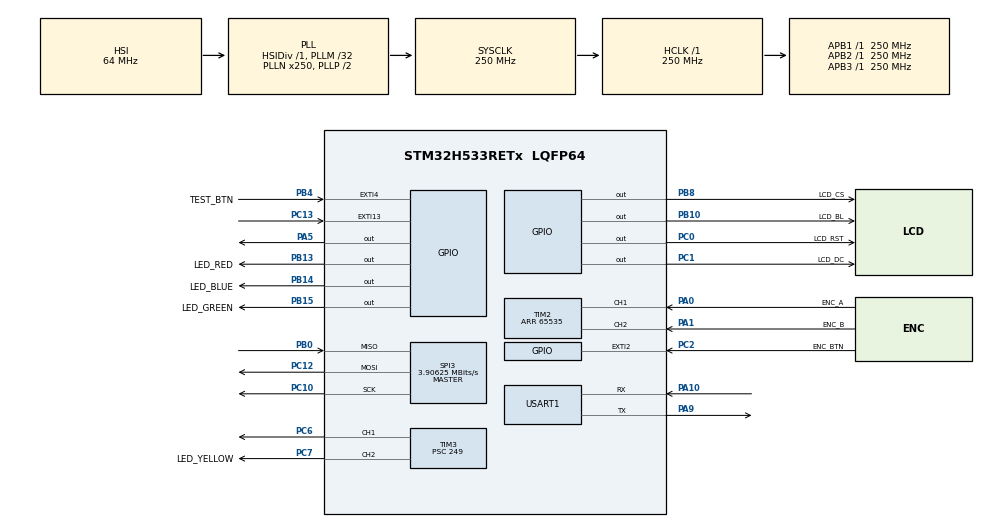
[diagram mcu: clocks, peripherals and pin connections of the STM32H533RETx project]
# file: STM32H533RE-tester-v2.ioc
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BOOTPATH.BootPathName=LEGACY
BOOTPATH.UserSelectedBootPath=LEGACY
CORTEX_M33_NS.userName=CORTEX_M33
GPDMA1.DESTBURSTLENGTH_GPDMACH0=1
GPDMA1.DESTINC_GPDMACH0=DMA_DINC_FIXED
GPDMA1.DIRECTION_GPDMACH0=DMA_MEMORY_TO_PERIPH
GPDMA1.IPHANDLE_GPDMACH0-SIMPLEREQUEST_GPDMACH0=__NULL
GPDMA1.REQUEST_GPDMACH0=GPDMA1_REQUEST_SPI3_TX
GPDMA1.SRCBURSTLENGTH_GPDMACH0=1
GPDMA1.SRCINC_GPDMACH0=DMA_SINC_INCREMENTED
Mcu.Family=STM32H5
Mcu.Name=STM32H533RETx
Mcu.Package=LQFP64
NUCLEO-H533RE.BUTTON=1
NUCLEO-H533RE.LD4=true
NUCLEO-H533RE.VCP=true
NVIC.EXTI13_IRQn=true\:0\:0\:false\:false\:true\:false\:true\:true
NVIC.EXTI2_IRQn=true\:0\:0\:false\:false\:true\:true\:true\:true
NVIC.EXTI4_IRQn=true\:0\:0\:false\:false\:true\:true\:true\:true
NVIC.GPDMA1_Channel0_IRQn=true\:0\:0\:false\:false\:true\:true\:true\:true
NVIC.PriorityGroup=NVIC_PRIORITYGROUP_4
NVIC.SPI3_IRQn=true\:0\:0\:false\:false\:true\:true\:true\:true
PA0.GPIO_Label=ENC_A
PA0.Signal=S_TIM2_CH1
PA1.GPIO_Label=ENC_B
PA1.Signal=S_TIM2_CH2
PA10.Mode=Asynchronous
PA10.Signal=USART1_RX
PA13(JTMS/SWDIO).GPIO_Label=SWDIO
PA13(JTMS/SWDIO).Signal=DEBUG_JTMS-SWDIO
PA14(JTCK/SWCLK).GPIO_Label=SWCLK
PA14(JTCK/SWCLK).Signal=DEBUG_JTCK-SWCLK
PA15(JTDI).GPIO_Label=JTDI
PA15(JTDI).Signal=DEBUG_JTDI
PA2.Signal=USART2_TX
PA3.Signal=USART2_RX
PA5.Signal=GPIO_Output
PA9.Mode=Asynchronous
PA9.Signal=USART1_TX
PB0.Mode=Full_Duplex_Master
PB0.Signal=SPI3_MISO
PB10.GPIO_Label=LCD_BL
PB10.Signal=GPIO_Output
PB13.GPIO_Label=LED_RED
PB13.PinState=GPIO_PIN_SET
PB13.Signal=GPIO_Output
PB14.GPIO_Label=LED_BLUE
PB14.PinState=GPIO_PIN_SET
PB14.Signal=GPIO_Output
PB15.GPIO_Label=LED_GREEN
PB15.PinState=GPIO_PIN_SET
PB15.Signal=GPIO_Output
PB3(JTDO/TRACESWO).GPIO_Label=SWO
PB3(JTDO/TRACESWO).Signal=DEBUG_JTDO-SWO
PB4(NJTRST).GPIO_Label=TEST_BTN
PB4(NJTRST).GPIO_ModeDefaultEXTI=GPIO_MODE_IT_FALLING
PB4(NJTRST).GPIO_PuPd=GPIO_PULLUP
PB4(NJTRST).Signal=GPXTI4
PB8.GPIO_Label=LCD_CS
PB8.Signal=GPIO_Output
PC0.GPIO_Label=LCD_RST
PC0.Signal=GPIO_Output
PC1.GPIO_Label=LCD_DC
PC1.Signal=GPIO_Output
PC10.Mode=Full_Duplex_Master
PC10.Signal=SPI3_SCK
PC12.Mode=Full_Duplex_Master
PC12.Signal=SPI3_MOSI
PC13.Signal=GPXTI13
PC2.GPIO_Label=ENC_BTN
PC2.GPIO_ModeDefaultEXTI=GPIO_MODE_IT_FALLING
PC2.GPIO_PuPd=GPIO_PULLUP
PC2.Signal=GPXTI2
PC6.Signal=S_TIM3_CH1
PC7.GPIO_Label=LED_YELLOW
PC7.Signal=S_TIM3_CH2
ProjectManager.HeapSize=0x200
ProjectManager.StackSize=0x400
ProjectManager.TargetToolchain=STM32CubeIDE
RCC.ADCFreq_Value=250000000
RCC.AHBFreq_Value=250000000
RCC.APB1Freq_Value=250000000
RCC.APB1TimFreq_Value=250000000
RCC.APB2Freq_Value=250000000
RCC.APB2TimFreq_Value=250000000
RCC.APB3Freq_Value=250000000
RCC.CSI_VALUE=4000000
RCC.CortexFreq_Value=250000000
RCC.EPOD_VALUE=64000000
RCC.HCLKFreq_Value=250000000
RCC.HSE_VALUE=8000000
RCC.HSI48_VALUE=48000000
RCC.HSIDiv=RCC_HSI_DIV1
RCC.HSI_VALUE=64000000
RCC.LSE_VALUE=32768
RCC.LSIRC_VALUE=32000
RCC.PLLM=32
RCC.PLLN=250
RCC.PLLSourceVirtual=RCC_PLL1_SOURCE_HSI
RCC.SYSCLKFreq_VALUE=250000000
RCC.SYSCLKSource=RCC_SYSCLKSOURCE_PLLCLK
RCC.USBFreq_Value=48000000
RCC.VCOOutputFreq_Value=500000000
SH.S_TIM2_CH1.0=TIM2_CH1,Encoder_Interface
SH.S_TIM2_CH2.0=TIM2_CH2,Encoder_Interface
SH.S_TIM3_CH1.0=TIM3_CH1,PWM Generation1 CH1
SH.S_TIM3_CH2.0=TIM3_CH2,PWM Generation2 CH2
SPI3.BaudRatePrescaler=SPI_BAUDRATEPRESCALER_64
SPI3.CLKPhase=SPI_PHASE_2EDGE
SPI3.CLKPolarity=SPI_POLARITY_HIGH
SPI3.CalculateBaudRate=3.90625 MBits/s
SPI3.DataSize=SPI_DATASIZE_8BIT
SPI3.Direction=SPI_DIRECTION_2LINES
SPI3.Mode=SPI_MODE_MASTER
SPI3.VirtualType=VM_MASTER
TIM2.PeriodNoDither=65535
TIM3.Channel-PWM\ Generation1\ CH1=TIM_CHANNEL_1
TIM3.Channel-PWM\ Generation2\ CH2=TIM_CHANNEL_2
TIM3.OCMode_PWM-PWM\ Generation1\ CH1=TIM_OCMODE_PWM1
TIM3.OCPolarity_2=TIM_OCPOLARITY_LOW
TIM3.PeriodNoDither=999
TIM3.Prescaler=249
TIM3.PulseNoDither_1=500
USART1.RxPinLevelInvertParam=ADVFEATURE_RXINV_DISABLE
USART1.TxPinLevelInvertParam=ADVFEATURE_TXINV_DISABLE
USART1.VirtualMode-Asynchronous=VM_ASYNC
VP_BOOTPATH_VS_BOOTPATH.Mode=BP_Activate
VP_CORTEX_M33_NS_VS_Hclk.Mode=Hclk_Mode
VP_GPDMA1_VS_GPDMACH0.Mode=SIMPLEREQUEST_GPDMACH0
VP_ICACHE_VS_ICACHE.Mode=DefaultMode
VP_MEMORYMAP_VS_MEMORYMAP.Mode=CurAppReg
VP_NUCLEO-H533RE_VS_BSP_COMMON.Mode=COMMON
VP_PWR_VS_LPOM.Mode=PowerOptimisation
VP_PWR_VS_SECSignals.Mode=Security/Privilege
VP_TIM3_VS_ClockSourceINT.Mode=Internal
board=NUCLEO-H533RE

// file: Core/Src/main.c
/* USER CODE BEGIN Header */
/**
  ******************************************************************************
  * @file           : main.c
  * @brief          : Main program body
  ******************************************************************************
  * @attention
  *
  * Copyright (c) 2025 STMicroelectronics.
  * All rights reserved.
  *
  * This software is licensed under terms that can be found in the LICENSE file
  * in the root directory of this software component.
  * If no LICENSE file comes with this software, it is provided AS-IS.
  *
  ******************************************************************************
  */
/* USER CODE END Header */
#include "main.h"

/* USER CODE BEGIN Includes */
#include "buttons.h"

/* USER CODE END Includes */

COM_InitTypeDef BspCOMInit;

SPI_HandleTypeDef hspi3;
DMA_HandleTypeDef handle_GPDMA1_Channel0;

TIM_HandleTypeDef htim2;
TIM_HandleTypeDef htim3;

UART_HandleTypeDef huart1;

void SystemClock_Config(void);
static void MX_GPIO_Init(void);
static void MX_GPDMA1_Init(void);
static void MX_ICACHE_Init(void);
static void MX_TIM3_Init(void);
static void MX_TIM2_Init(void);
static void MX_SPI3_Init(void);
static void MX_USART1_UART_Init(void);

int main(void)
{

  /* MCU Configuration--------------------------------------------------------*/

  /* Reset of all peripherals, Initializes the Flash interface and the Systick. */
  HAL_Init();

  /* Configure the system clock */
  SystemClock_Config();

  /* Initialize all configured peripherals */
  MX_GPIO_Init();
  MX_GPDMA1_Init();
  MX_ICACHE_Init();
  MX_TIM3_Init();
  MX_TIM2_Init();
  MX_SPI3_Init();
  MX_USART1_UART_Init();
  /* USER CODE BEGIN 2 */

  // Inicjalizacja warstwy aplikacji
  app_init();

  /* USER CODE END 2 */

  /* Initialize leds */
  BSP_LED_Init(LED_GREEN);

  /* Initialize USER push-button, will be used to trigger an interrupt each time it's pressed.*/
  BSP_PB_Init(BUTTON_USER, BUTTON_MODE_EXTI);

  /* Initialize COM1 port (115200, 8 bits (7-bit data + 1 stop bit), no parity */
  BspCOMInit.BaudRate   = 115200;
  BspCOMInit.WordLength = COM_WORDLENGTH_8B;
  BspCOMInit.StopBits   = COM_STOPBITS_1;
  BspCOMInit.Parity     = COM_PARITY_NONE;
  BspCOMInit.HwFlowCtl  = COM_HWCONTROL_NONE;
  if (BSP_COM_Init(COM1, &BspCOMInit) != BSP_ERROR_NONE)
  {
    Error_Handler();
  }

  /* Infinite loop */
  /* USER CODE BEGIN WHILE */
  while (1)
  {
    // Główna pętla aplikacji
    app_process();
    /* USER CODE END WHILE */

  }
}

void SystemClock_Config(void)
{
  RCC_OscInitTypeDef RCC_OscInitStruct = {0};
  RCC_ClkInitTypeDef RCC_ClkInitStruct = {0};

  /** Configure the main internal regulator output voltage
  */
  __HAL_PWR_VOLTAGESCALING_CONFIG(PWR_REGULATOR_VOLTAGE_SCALE0);

  while(!__HAL_PWR_GET_FLAG(PWR_FLAG_VOSRDY)) {}

  /** Initializes the RCC Oscillators according to the specified parameters
  * in the RCC_OscInitTypeDef structure.
  */
  RCC_OscInitStruct.OscillatorType = RCC_OSCILLATORTYPE_HSI;
  RCC_OscInitStruct.HSIState = RCC_HSI_ON;
  RCC_OscInitStruct.HSIDiv = RCC_HSI_DIV1;
  RCC_OscInitStruct.HSICalibrationValue = RCC_HSICALIBRATION_DEFAULT;
  RCC_OscInitStruct.PLL.PLLState = RCC_PLL_ON;
  RCC_OscInitStruct.PLL.PLLSource = RCC_PLL1_SOURCE_HSI;
  RCC_OscInitStruct.PLL.PLLM = 32;
  RCC_OscInitStruct.PLL.PLLN = 250;
  RCC_OscInitStruct.PLL.PLLP = 2;
  RCC_OscInitStruct.PLL.PLLQ = 2;
  RCC_OscInitStruct.PLL.PLLR = 2;
  RCC_OscInitStruct.PLL.PLLRGE = RCC_PLL1_VCIRANGE_1;
  RCC_OscInitStruct.PLL.PLLVCOSEL = RCC_PLL1_VCORANGE_WIDE;
  RCC_OscInitStruct.PLL.PLLFRACN = 0;
  if (HAL_RCC_OscConfig(&RCC_OscInitStruct) != HAL_OK)
  {
    Error_Handler();
  }

  /** Initializes the CPU, AHB and APB buses clocks
  */
  RCC_ClkInitStruct.ClockType = RCC_CLOCKTYPE_HCLK|RCC_CLOCKTYPE_SYSCLK
                              |RCC_CLOCKTYPE_PCLK1|RCC_CLOCKTYPE_PCLK2
                              |RCC_CLOCKTYPE_PCLK3;
  RCC_ClkInitStruct.SYSCLKSource = RCC_SYSCLKSOURCE_PLLCLK;
  RCC_ClkInitStruct.AHBCLKDivider = RCC_SYSCLK_DIV1;
  RCC_ClkInitStruct.APB1CLKDivider = RCC_HCLK_DIV1;
  RCC_ClkInitStruct.APB2CLKDivider = RCC_HCLK_DIV1;
  RCC_ClkInitStruct.APB3CLKDivider = RCC_HCLK_DIV1;

  if (HAL_RCC_ClockConfig(&RCC_ClkInitStruct, FLASH_LATENCY_5) != HAL_OK)
  {
    Error_Handler();
  }

  /** Configure the programming delay
  */
  __HAL_FLASH_SET_PROGRAM_DELAY(FLASH_PROGRAMMING_DELAY_2);
}

static void MX_GPDMA1_Init(void)
{

  /* Peripheral clock enable */
  __HAL_RCC_GPDMA1_CLK_ENABLE();

  /* GPDMA1 interrupt Init */
    HAL_NVIC_SetPriority(GPDMA1_Channel0_IRQn, 0, 0);
    HAL_NVIC_EnableIRQ(GPDMA1_Channel0_IRQn);

}

static void MX_ICACHE_Init(void)
{

  /** Enable instruction cache (default 2-ways set associative cache)
  */
  if (HAL_ICACHE_Enable() != HAL_OK)
  {
    Error_Handler();
  }

}

static void MX_SPI3_Init(void)
{

  /* SPI3 parameter configuration*/
  hspi3.Instance = SPI3;
  hspi3.Init.Mode = SPI_MODE_MASTER;
  hspi3.Init.Direction = SPI_DIRECTION_2LINES;
  hspi3.Init.DataSize = SPI_DATASIZE_8BIT;
  hspi3.Init.CLKPolarity = SPI_POLARITY_HIGH;
  hspi3.Init.CLKPhase = SPI_PHASE_2EDGE;
  hspi3.Init.NSS = SPI_NSS_SOFT;
  hspi3.Init.BaudRatePrescaler = SPI_BAUDRATEPRESCALER_64;
  hspi3.Init.FirstBit = SPI_FIRSTBIT_MSB;
  hspi3.Init.TIMode = SPI_TIMODE_DISABLE;
  hspi3.Init.CRCCalculation = SPI_CRCCALCULATION_DISABLE;
  hspi3.Init.CRCPolynomial = 0x7;
  hspi3.Init.NSSPMode = SPI_NSS_PULSE_DISABLE;
  hspi3.Init.NSSPolarity = SPI_NSS_POLARITY_LOW;
  hspi3.Init.FifoThreshold = SPI_FIFO_THRESHOLD_01DATA;
  hspi3.Init.MasterSSIdleness = SPI_MASTER_SS_IDLENESS_00CYCLE;
  hspi3.Init.MasterInterDataIdleness = SPI_MASTER_INTERDATA_IDLENESS_00CYCLE;
  hspi3.Init.MasterReceiverAutoSusp = SPI_MASTER_RX_AUTOSUSP_DISABLE;
  hspi3.Init.MasterKeepIOState = SPI_MASTER_KEEP_IO_STATE_DISABLE;
  hspi3.Init.IOSwap = SPI_IO_SWAP_DISABLE;
  hspi3.Init.ReadyMasterManagement = SPI_RDY_MASTER_MANAGEMENT_INTERNALLY;
  hspi3.Init.ReadyPolarity = SPI_RDY_POLARITY_HIGH;
  if (HAL_SPI_Init(&hspi3) != HAL_OK)
  {
    Error_Handler();
  }

}

static void MX_TIM2_Init(void)
{

  TIM_Encoder_InitTypeDef sConfig = {0};
  TIM_MasterConfigTypeDef sMasterConfig = {0};

  htim2.Instance = TIM2;
  htim2.Init.Prescaler = 0;
  htim2.Init.CounterMode = TIM_COUNTERMODE_UP;
  htim2.Init.Period = 65535;
  htim2.Init.ClockDivision = TIM_CLOCKDIVISION_DIV1;
  htim2.Init.AutoReloadPreload = TIM_AUTORELOAD_PRELOAD_DISABLE;
  sConfig.EncoderMode = TIM_ENCODERMODE_TI1;
  sConfig.IC1Polarity = TIM_ICPOLARITY_RISING;
  sConfig.IC1Selection = TIM_ICSELECTION_DIRECTTI;
  sConfig.IC1Prescaler = TIM_ICPSC_DIV1;
  sConfig.IC1Filter = 0;
  sConfig.IC2Polarity = TIM_ICPOLARITY_RISING;
  sConfig.IC2Selection = TIM_ICSELECTION_DIRECTTI;
  sConfig.IC2Prescaler = TIM_ICPSC_DIV1;
  sConfig.IC2Filter = 0;
  if (HAL_TIM_Encoder_Init(&htim2, &sConfig) != HAL_OK)
  {
    Error_Handler();
  }
  sMasterConfig.MasterOutputTrigger = TIM_TRGO_RESET;
  sMasterConfig.MasterSlaveMode = TIM_MASTERSLAVEMODE_DISABLE;
  if (HAL_TIMEx_MasterConfigSynchronization(&htim2, &sMasterConfig) != HAL_OK)
  {
    Error_Handler();
  }

}

static void MX_TIM3_Init(void)
{

  TIM_ClockConfigTypeDef sClockSourceConfig = {0};
  TIM_MasterConfigTypeDef sMasterConfig = {0};
  TIM_OC_InitTypeDef sConfigOC = {0};

  htim3.Instance = TIM3;
  htim3.Init.Prescaler = 249;
  htim3.Init.CounterMode = TIM_COUNTERMODE_UP;
  htim3.Init.Period = 999;
  htim3.Init.ClockDivision = TIM_CLOCKDIVISION_DIV1;
  htim3.Init.AutoReloadPreload = TIM_AUTORELOAD_PRELOAD_DISABLE;
  if (HAL_TIM_Base_Init(&htim3) != HAL_OK)
  {
    Error_Handler();
  }
  sClockSourceConfig.ClockSource = TIM_CLOCKSOURCE_INTERNAL;
  if (HAL_TIM_ConfigClockSource(&htim3, &sClockSourceConfig) != HAL_OK)
  {
    Error_Handler();
  }
  if (HAL_TIM_PWM_Init(&htim3) != HAL_OK)
  {
    Error_Handler();
  }
  sMasterConfig.MasterOutputTrigger = TIM_TRGO_RESET;
  sMasterConfig.MasterSlaveMode = TIM_MASTERSLAVEMODE_DISABLE;
  if (HAL_TIMEx_MasterConfigSynchronization(&htim3, &sMasterConfig) != HAL_OK)
  {
    Error_Handler();
  }
  sConfigOC.OCMode = TIM_OCMODE_PWM1;
  sConfigOC.Pulse = 500;
  sConfigOC.OCPolarity = TIM_OCPOLARITY_HIGH;
  sConfigOC.OCFastMode = TIM_OCFAST_DISABLE;
  if (HAL_TIM_PWM_ConfigChannel(&htim3, &sConfigOC, TIM_CHANNEL_1) != HAL_OK)
  {
    Error_Handler();
  }
  sConfigOC.Pulse = 0;
  sConfigOC.OCPolarity = TIM_OCPOLARITY_LOW;
  if (HAL_TIM_PWM_ConfigChannel(&htim3, &sConfigOC, TIM_CHANNEL_2) != HAL_OK)
  {
    Error_Handler();
  }
  HAL_TIM_MspPostInit(&htim3);

}

static void MX_USART1_UART_Init(void)
{

  huart1.Instance = USART1;
  huart1.Init.BaudRate = 115200;
  huart1.Init.WordLength = UART_WORDLENGTH_8B;
  huart1.Init.StopBits = UART_STOPBITS_1;
  huart1.Init.Parity = UART_PARITY_NONE;
  huart1.Init.Mode = UART_MODE_TX_RX;
  huart1.Init.HwFlowCtl = UART_HWCONTROL_NONE;
  huart1.Init.OverSampling = UART_OVERSAMPLING_16;
  huart1.Init.OneBitSampling = UART_ONE_BIT_SAMPLE_DISABLE;
  huart1.Init.ClockPrescaler = UART_PRESCALER_DIV1;
  huart1.AdvancedInit.AdvFeatureInit = UART_ADVFEATURE_NO_INIT;
  if (HAL_UART_Init(&huart1) != HAL_OK)
  {
    Error_Handler();
  }
  if (HAL_UARTEx_SetTxFifoThreshold(&huart1, UART_TXFIFO_THRESHOLD_1_8) != HAL_OK)
  {
    Error_Handler();
  }
  if (HAL_UARTEx_SetRxFifoThreshold(&huart1, UART_RXFIFO_THRESHOLD_1_8) != HAL_OK)
  {
    Error_Handler();
  }
  if (HAL_UARTEx_DisableFifoMode(&huart1) != HAL_OK)
  {
    Error_Handler();
  }

}

static void MX_GPIO_Init(void)
{
  GPIO_InitTypeDef GPIO_InitStruct = {0};

  /* GPIO Ports Clock Enable */
  __HAL_RCC_GPIOC_CLK_ENABLE();
  __HAL_RCC_GPIOA_CLK_ENABLE();
  __HAL_RCC_GPIOB_CLK_ENABLE();

  /*Configure GPIO pin Output Level */
  HAL_GPIO_WritePin(GPIOC, LCD_RST_Pin|LCD_DC_Pin, GPIO_PIN_RESET);

  /*Configure GPIO pin Output Level */
  HAL_GPIO_WritePin(GPIOB, LCD_BL_Pin|LCD_CS_Pin, GPIO_PIN_RESET);

  /*Configure GPIO pin Output Level */
  HAL_GPIO_WritePin(GPIOB, LED_RED_Pin|LED_BLUE_Pin|LED_GREEN_Pin, GPIO_PIN_SET);

  /*Configure GPIO pins : LCD_RST_Pin LCD_DC_Pin */
  GPIO_InitStruct.Pin = LCD_RST_Pin|LCD_DC_Pin;
  GPIO_InitStruct.Mode = GPIO_MODE_OUTPUT_PP;
  GPIO_InitStruct.Pull = GPIO_NOPULL;
  GPIO_InitStruct.Speed = GPIO_SPEED_FREQ_LOW;
  HAL_GPIO_Init(GPIOC, &GPIO_InitStruct);

  /*Configure GPIO pin : ENC_BTN_Pin */
  GPIO_InitStruct.Pin = ENC_BTN_Pin;
  GPIO_InitStruct.Mode = GPIO_MODE_IT_FALLING;
  GPIO_InitStruct.Pull = GPIO_PULLUP;
  HAL_GPIO_Init(ENC_BTN_GPIO_Port, &GPIO_InitStruct);

  /*Configure GPIO pins : LCD_BL_Pin LED_RED_Pin LED_BLUE_Pin LED_GREEN_Pin
                           LCD_CS_Pin */
  GPIO_InitStruct.Pin = LCD_BL_Pin|LED_RED_Pin|LED_BLUE_Pin|LED_GREEN_Pin
                          |LCD_CS_Pin;
  GPIO_InitStruct.Mode = GPIO_MODE_OUTPUT_PP;
  GPIO_InitStruct.Pull = GPIO_NOPULL;
  GPIO_InitStruct.Speed = GPIO_SPEED_FREQ_LOW;
  HAL_GPIO_Init(GPIOB, &GPIO_InitStruct);

  /*Configure GPIO pin : TEST_BTN_Pin */
  GPIO_InitStruct.Pin = TEST_BTN_Pin;
  GPIO_InitStruct.Mode = GPIO_MODE_IT_FALLING;
  GPIO_InitStruct.Pull = GPIO_PULLUP;
  HAL_GPIO_Init(TEST_BTN_GPIO_Port, &GPIO_InitStruct);

  /* EXTI interrupt init*/
  HAL_NVIC_SetPriority(EXTI2_IRQn, 0, 0);
  HAL_NVIC_EnableIRQ(EXTI2_IRQn);

  HAL_NVIC_SetPriority(EXTI4_IRQn, 0, 0);
  HAL_NVIC_EnableIRQ(EXTI4_IRQn);

}

/* USER CODE BEGIN 4 */
void HAL_GPIO_EXTI_Falling_Callback(uint16_t GPIO_Pin)
{
  // Forward interrupt notification to the button module
  buttons_irq_callback(GPIO_Pin);
}

void BSP_PB_Callback(Button_TypeDef Button)
{
  if (Button == BUTTON_USER) {
    buttons_irq_callback(BUTTON_USER_PIN);
  }
}

/* USER CODE END 4 */

void Error_Handler(void)
{
  __disable_irq();
  while (1)
  {
  }
}
